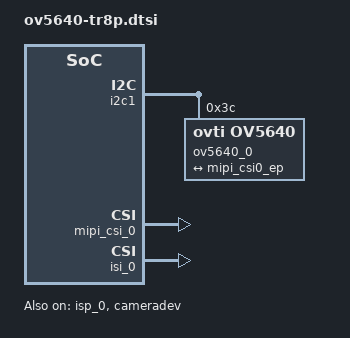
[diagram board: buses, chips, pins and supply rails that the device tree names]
/*
 * Copyright 2022 SECO Northern Europe GmbH
 *
 */

/*
Remarks:
Defines:
*/

#ifndef OV5640_TR8P_DTSI
#define OV5640_TR8P_DTSI

&i2c1 {
	ov5640_0: ov5640_mipi@3c {
		compatible = "ovti,ov5640";
		reg = <0x3c>;
		pinctrl-names = "default";
		pinctrl-0 = <&pinctrl_camera0>;
		clocks = <&clk IMX8MP_CLK_IPP_DO_CLKO2>;
		clock-names = "xclk";
		assigned-clocks = <&clk IMX8MP_CLK_IPP_DO_CLKO2>;
		assigned-clock-parents = <&clk IMX8MP_CLK_24M>;
		assigned-clock-rates = <24000000>;
		csi_id = <0>;
		powerdown-gpios = <camera_pwdn GPIO_ACTIVE_HIGH>;
		reset-gpios = <camera_reset GPIO_ACTIVE_LOW>;
		mclk = <24000000>;
		mclk_source = <0>;
		mipi_csi;
		status = "okay";

		port {
			camera_mipi_0_ep: endpoint {
				remote-endpoint = <&mipi_csi0_ep>;
				data-lanes = <1 2>;
				clock-lanes = <0>;
			};
		};
	};
};


&mipi_csi_0 {
	status = "okay";
};

&mipi_csi0_ep {
	remote-endpoint = <&camera_mipi_0_ep>;
};

&isi_0 {
	status = "okay";

	cap_device {
		status = "okay";
	};
};

&isp_0 {
	status = "okay";
};

&cameradev {
	status = "okay";
};

#endif
